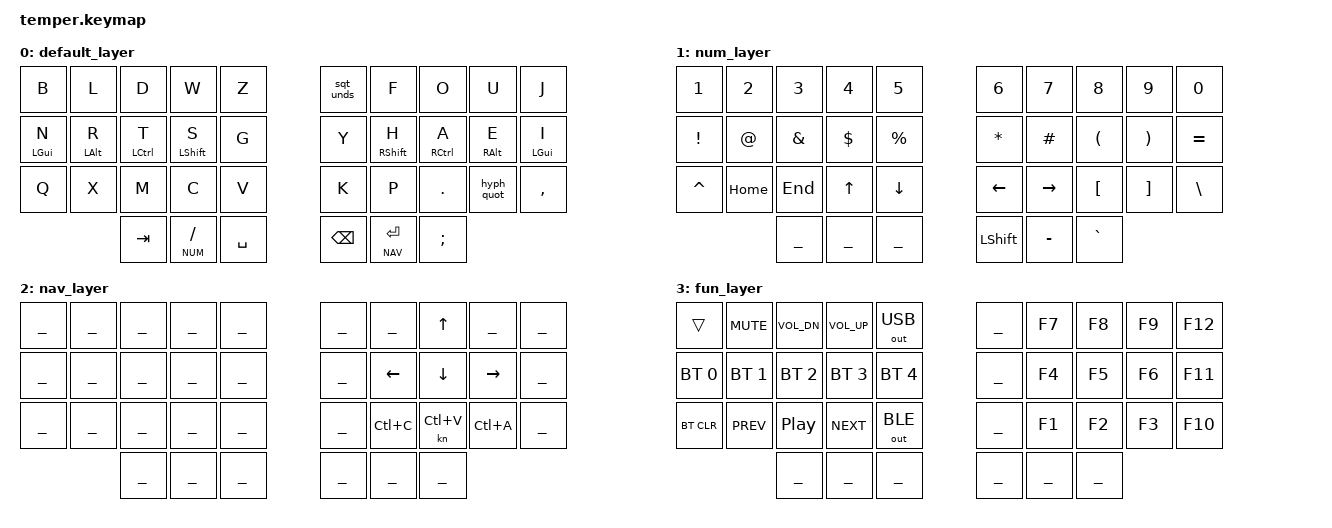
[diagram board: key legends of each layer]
/*
 * Copyright (c) 2020 The ZMK Contributors
 *
 * SPDX-License-Identifier: MIT
 */

#include <behaviors.dtsi>
#include <dt-bindings/zmk/keys.h>
#include <dt-bindings/zmk/bt.h>
#include <dt-bindings/zmk/outputs.h>

#define GRAPHITE 0
#define NUM 1
#define NAV 2
#define FUN 3

/ {

    conditional_layers {
        compatible = "zmk,conditional-layers";
        tri_layer {
            if-layers = <NUM NAV>;
            then-layer = <FUN>;
        };
    };
   
    behaviors {
        sqt_unds: apostrophe_underscore {
            compatible = "zmk,behavior-mod-morph";
            #binding-cells = <0>;
            bindings = <&kp SQT>, <&kp UNDER>;
            mods = <(MOD_LSHFT|MOD_RSHFT)>;
            keep-mods = <(MOD_RSHFT)>;
        };
        hyph_quot: hyphen_doublequotes {
            compatible = "zmk,behavior-mod-morph";
            #binding-cells = <0>;
            bindings = <&kp MINUS>, <&kp DQT>;
            mods = <(MOD_LSHFT|MOD_RSHFT)>;
            keep-mods = <(MOD_RSHFT)>;
        };
        
    };
        keymap {
                compatible = "zmk,keymap";

                default_layer {
                        bindings = <
// ╭─────────────┬─────────────┬─────────────┬─────────────┬─────────────╮   ╭─────────────┬─────────────┬─────────────┬─────────────┬─────────────╮
        &kp B         &kp L         &kp D         &kp W         &kp Z             &sqt_unds    &kp F         &kp O         &kp U       &kp J   
// ├─────────────┼─────────────┼─────────────┼─────────────┼─────────────┤   ├─────────────┼─────────────┼─────────────┼─────────────┼─────────────┤
     &mt LGUI N    &mt LALT R     &mt LCTRL T  &mt LSHFT S      &kp G             &kp Y      &mt RSHFT H   &mt RCTRL A    &mt RALT E    &mt LGUI I
// ├─────────────┼─────────────┼─────────────┼─────────────┼─────────────┤   ├─────────────┼─────────────┼─────────────┼─────────────┼─────────────┤
        &kp Q         &kp X         &kp M         &kp C         &kp V             &kp K         &kp P        &kp DOT     &hyph_quot    &kp COMMA
// ╰─────────────┴─────────────┼─────────────┼─────────────┼─────────────┤   ├─────────────┼─────────────┼─────────────┼─────────────┴─────────────╯
                                 &kp TAB       &lt NUM SLASH &kp SPACE         &kp BACKSPACE  &lt  NAV ENTER   &kp SEMI
//                             ╰─────────────┴─────────────┴─────────────╯   ╰─────────────┴─────────────┴─────────────╯
                        >;
                };
                num_layer {
                        bindings = <
// ╭─────────────┬─────────────┬─────────────┬─────────────┬─────────────╮   ╭─────────────┬─────────────┬─────────────┬─────────────┬─────────────╮
        &kp N1       &kp N2         &kp N3       &kp N4      &kp N5            &kp N6       &kp N7        &kp N8        &kp N9        &kp N0  
// ├─────────────┼─────────────┼─────────────┼─────────────┼─────────────┤   ├─────────────┼─────────────┼─────────────┼─────────────┼─────────────┤
       &kp EXCL    &kp AT        &kp AMPS     &kp DLLR         &kp PRCNT          &kp STAR      &kp HASH        &kp LPAR        &kp RPAR    &kp EQUAL
// ├─────────────┼─────────────┼─────────────┼─────────────┼─────────────┤   ├─────────────┼─────────────┼─────────────┼─────────────┼─────────────┤
       &kp CARET       &kp HOME   &kp END         &kp UP       &kp DOWN          &kp LEFT       &kp RIGHT    &kp LBKT     &kp RBKT      &kp BSLH
// ╰─────────────┴─────────────┼─────────────┼─────────────┼─────────────┤   ├─────────────┼─────────────┼─────────────┼─────────────┴─────────────╯
                                    ______     ______    ______            &kp LSHFT     &kp MINUS     &kp GRAVE
//                             ╰─────────────┴─────────────┴─────────────╯   ╰─────────────┴─────────────┴─────────────╯
                        >;
                };
                nav_layer {
                        bindings = <
// ╭─────────────┬─────────────┬─────────────┬─────────────┬─────────────╮   ╭─────────────┬─────────────┬─────────────┬─────────────┬─────────────╮
        ______       ______         ______       ______      ______             ______         ______        &kp UP        ______        ______  
// ├─────────────┼─────────────┼─────────────┼─────────────┼─────────────┤   ├─────────────┼─────────────┼─────────────┼─────────────┼─────────────┤
       ______         ______      ______       ______        ______              ______      &kp LEFT       &kp DOWN        &kp RIGHT    ______
// ├─────────────┼─────────────┼─────────────┼─────────────┼─────────────┤   ├─────────────┼─────────────┼─────────────┼─────────────┼─────────────┤
       ______       ______      ______         ______       ______               ______       &kp LC(C)     &kn LC(V)      &kp LC(A)    ______
// ╰─────────────┴─────────────┼─────────────┼─────────────┼─────────────┤   ├─────────────┼─────────────┼─────────────┼─────────────┴─────────────╯
                                    ______      ______          ______            ______        ______       ______
//                             ╰─────────────┴─────────────┴─────────────╯   ╰─────────────┴─────────────┴─────────────╯
                        >;
                };


                fun_layer {
                        bindings = <
// ╭─────────────┬─────────────┬─────────────┬─────────────┬─────────────╮   ╭─────────────┬─────────────┬─────────────┬─────────────┬─────────────╮
      &trans       &kp K_MUTE    &kp C_VOL_DN  &kp C_VOL_UP  &out OUT_USB         ______        &kp F7        &kp F8        &kp F9       &kp F12
// ├─────────────┼─────────────┼─────────────┼─────────────┼─────────────┤   ├─────────────┼─────────────┼─────────────┼─────────────┼─────────────┤
     &bt BT_SEL 0  &bt BT_SEL 1  &bt BT_SEL 2  &bt BT_SEL 3  &bt BT_SEL 4         ______        &kp F4        &kp F5        &kp F6       &kp F11
// ├─────────────┼─────────────┼─────────────┼─────────────┼─────────────┤   ├─────────────┼─────────────┼─────────────┼─────────────┼─────────────┤
      &bt BT_CLR    &kp C_PREV     &kp C_PP     &kp C_NEXT   &out OUT_BLE         ______        &kp F1        &kp F2        &kp F3       &kp F10
// ╰─────────────┴─────────────┼─────────────┼─────────────┼─────────────┤   ├─────────────┼─────────────┼─────────────┼─────────────┴─────────────╯
                                    ______        ______        ______            ______        ______        ______
//                             ╰─────────────┴─────────────┴─────────────╯   ╰─────────────┴─────────────┴─────────────╯
                        >;
                };
        };
};
